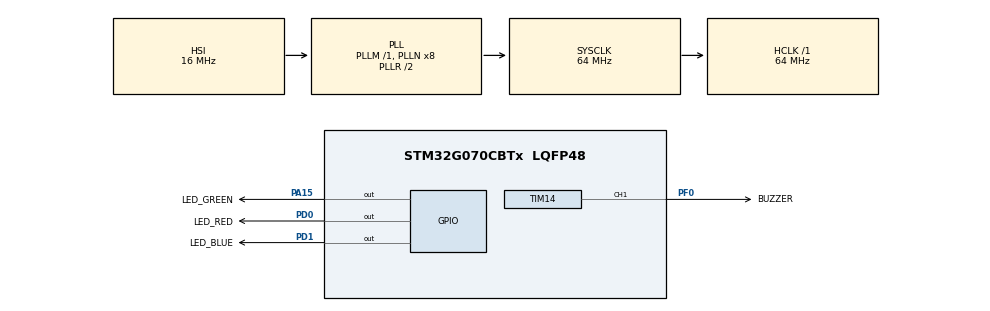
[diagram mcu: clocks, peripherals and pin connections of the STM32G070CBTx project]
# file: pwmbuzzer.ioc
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Mcu.Family=STM32G0
Mcu.Name=STM32G070CBTx
Mcu.Package=LQFP48
PA13.Mode=Serial_Wire
PA13.Signal=SYS_SWDIO
PA14-BOOT0.Mode=Serial_Wire
PA14-BOOT0.Signal=SYS_SWCLK
PA15.GPIO_Label=LED_GREEN
PA15.PinState=GPIO_PIN_SET
PA15.Signal=GPIO_Output
PD0.GPIO_Label=LED_RED
PD0.PinState=GPIO_PIN_SET
PD0.Signal=GPIO_Output
PD1.GPIO_Label=LED_BLUE
PD1.PinState=GPIO_PIN_SET
PD1.Signal=GPIO_Output
PF0-OSC_IN\ (PF0).GPIO_Label=BUZZER
PF0-OSC_IN\ (PF0).Signal=S_TIM14_CH1
ProjectManager.HeapSize=0x200
ProjectManager.StackSize=0x400
ProjectManager.TargetToolchain=MDK-ARM V5
RCC.ADCFreq_Value=64000000
RCC.AHBFreq_Value=64000000
RCC.CortexFreq_Value=64000000
RCC.EXTERNAL_CLOCK_VALUE=48000
RCC.HCLKFreq_Value=64000000
RCC.HSE_VALUE=8000000
RCC.HSI_VALUE=16000000
RCC.LSE_VALUE=32768
RCC.SYSCLKFreq_VALUE=64000000
RCC.SYSCLKSource=RCC_SYSCLKSOURCE_PLLCLK
RCC.VCOOutputFreq_Value=128000000
RealThread.RT-Thread.3.1.5.RTOSJjdevice=true
RealThread.RT-Thread.3.1.5.RTOSJjkernel=true
RealThread.RT-Thread.3.1.5.RTOSJjshell=true
SH.S_TIM14_CH1.0=TIM14_CH1,PWM Generation1 CH1
TIM14.AutoReloadPreload=TIM_AUTORELOAD_PRELOAD_ENABLE
TIM14.Channel=TIM_CHANNEL_1
TIM14.Period=1000
TIM14.Prescaler=64-1
VP_SYS_VS_DBSignals.Mode=DisableDeadBatterySignals
VP_TIM14_VS_ClockSourceINT.Mode=Enable_Timer
board=custom

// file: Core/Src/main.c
/* USER CODE BEGIN Header */
/**
  ******************************************************************************
  * @file           : main.c
  * @brief          : Main program body
  ******************************************************************************
  * @attention
  *
  * <h2><center>&copy; Copyright (c) 2022 STMicroelectronics.
  * All rights reserved.</center></h2>
  *
  * This software component is licensed by ST under Ultimate Liberty license
  * SLA0044, the "License"; You may not use this file except in compliance with
  * the License. You may obtain a copy of the License at:
  *                             www.st.com/SLA0044
  *
  ******************************************************************************
  */
/* USER CODE END Header */
#include "main.h"
#include "tim.h"
#include "gpio.h"

/* USER CODE BEGIN Includes */
#include "bsp_led.h"
#include "bsp_time.h"
#include "bsp_pwmbuzzer.h"
/* USER CODE END Includes */

void SystemClock_Config(void);

int main(void)
{

  /* MCU Configuration--------------------------------------------------------*/

  /* Reset of all peripherals, Initializes the Flash interface and the Systick. */
  HAL_Init();

  /* Configure the system clock */
  SystemClock_Config();

  /* Initialize all configured peripherals */
  MX_GPIO_Init();
  MX_TIM14_Init();
  /* USER CODE BEGIN 2 */
    BSP_Time_Init();
    BSP_LED_Init();
    BSP_PWMBuzzer_Init();
  /* USER CODE END 2 */

  /* Infinite loop */
  /* USER CODE BEGIN WHILE */
  while (1)
  {
    if(BSP_Time_CheckTick() == 1)
    {
        if(BSP_Time_CheckSlice(500) == 1)
        {
            BSP_LED_Toggle(GREEN);
        }
        if(BSP_Time_CheckSlice(200) == 1)
        {
            BSP_PWMBuzzer_Test();
        }
    }
    /* USER CODE END WHILE */

  }
}

void SystemClock_Config(void)
{
  RCC_OscInitTypeDef RCC_OscInitStruct = {0};
  RCC_ClkInitTypeDef RCC_ClkInitStruct = {0};

  /** Configure the main internal regulator output voltage
  */
  HAL_PWREx_ControlVoltageScaling(PWR_REGULATOR_VOLTAGE_SCALE1);
  /** Initializes the RCC Oscillators according to the specified parameters
  * in the RCC_OscInitTypeDef structure.
  */
  RCC_OscInitStruct.OscillatorType = RCC_OSCILLATORTYPE_HSI;
  RCC_OscInitStruct.HSIState = RCC_HSI_ON;
  RCC_OscInitStruct.HSIDiv = RCC_HSI_DIV1;
  RCC_OscInitStruct.HSICalibrationValue = RCC_HSICALIBRATION_DEFAULT;
  RCC_OscInitStruct.PLL.PLLState = RCC_PLL_ON;
  RCC_OscInitStruct.PLL.PLLSource = RCC_PLLSOURCE_HSI;
  RCC_OscInitStruct.PLL.PLLM = RCC_PLLM_DIV1;
  RCC_OscInitStruct.PLL.PLLN = 8;
  RCC_OscInitStruct.PLL.PLLP = RCC_PLLP_DIV2;
  RCC_OscInitStruct.PLL.PLLR = RCC_PLLR_DIV2;
  if (HAL_RCC_OscConfig(&RCC_OscInitStruct) != HAL_OK)
  {
    Error_Handler();
  }
  /** Initializes the CPU, AHB and APB buses clocks
  */
  RCC_ClkInitStruct.ClockType = RCC_CLOCKTYPE_HCLK|RCC_CLOCKTYPE_SYSCLK
                              |RCC_CLOCKTYPE_PCLK1;
  RCC_ClkInitStruct.SYSCLKSource = RCC_SYSCLKSOURCE_PLLCLK;
  RCC_ClkInitStruct.AHBCLKDivider = RCC_SYSCLK_DIV1;
  RCC_ClkInitStruct.APB1CLKDivider = RCC_HCLK_DIV1;

  if (HAL_RCC_ClockConfig(&RCC_ClkInitStruct, FLASH_LATENCY_2) != HAL_OK)
  {
    Error_Handler();
  }
}

void Error_Handler(void)
{
  __disable_irq();
  while (1)
  {
  }
}

/************************ (C) COPYRIGHT STMicroelectronics *****END OF FILE****/
